# STM32N655 register map
File version: 1.0
CPU: CM55 r0p1, little endian, no MPU, FPU, vendor SysTick, 8 interrupt priority bits
Registers are 32-bit, read-write, reset 0x0 unless marked. A register's access mark holds for its fields unless they carry their own. Offsets are from the block's base; [hi:lo] are bit positions; {n}, {i} and the like mark numbered series; 'fields as' and 'values as' point back to an identical list.

## RCC (part 1 of 4) — Reset and clock control
Base 0x46028000
Same registers: RCC_S 0x56028000
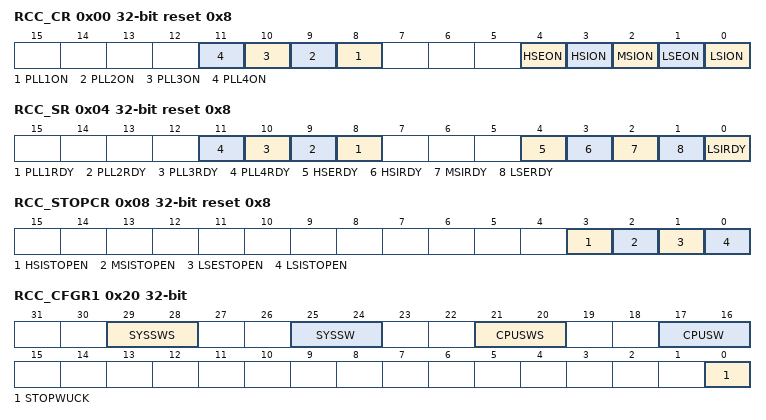
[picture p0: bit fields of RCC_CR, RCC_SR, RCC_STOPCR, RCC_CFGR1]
0x00 RCC_CR reset 0x8 — RCC control register
  [n+7] PLL{n}ON (n=1..4) — PLL{n} enable in Run/Sleep mode.
    0=PLL{n} is OFF (default after reset); 1=PLL{n} is ON
  [4] HSEON — HSE oscillator enable in Run/Sleep mode.
    0=HSE is OFF (default after reset); 1=HSE is ON
  [3] HSION — HSI oscillator enable in Run/Sleep mode.
    0=HSI is OFF; 1=HSI is ON (default after reset)
  [2] MSION — MSI oscillator enable in Run/Sleep mode.
    0=MSI is OFF (default after reset); 1=MSI is ON
  [1] LSEON — LSE oscillator enable in Run/Sleep mode.
    0=LSE is OFF (default after reset); 1=LSE is ON
  [0] LSION — LSI oscillator enable in Run/Sleep mode.
    0=LSI is OFF (default after reset); 1=LSI is ON
0x04 RCC_SR ro reset 0x8 — RCC status register
  [n+7] PLL{n}RDY (n=1..4) — PLL{n} clock ready flag
    0=PLL{n} unlocked (default after reset); 1=PLL{n} locked
  [4] HSERDY — HSE clock ready flag
    0=HSE is not ready (default after reset); 1=HSE is ready
  [3] HSIRDY — HSI clock ready flag
    0=HSI is not ready; 1=HSI is ready (default after reset)
  [2] MSIRDY — MSI clock ready flag
    0=MSI is not ready (default after reset); 1=MSI is ready
  [1] LSERDY — LSE clock ready flag
    0=LSE is not ready (default after reset); 1=LSE is ready
  [0] LSIRDY — LSI clock ready flag
    0=LSI is not ready (default after reset); 1=LSI is ready
0x08 RCC_STOPCR reset 0x8 — RCC Stop mode control register
  [3] HSISTOPEN — HSI oscillator enable in Stop mode.
    0=HSI is OFF; 1=HSI is ON (default after reset)
  [2] MSISTOPEN — MSI oscillator enable in Stop mode.
    0=MSI is OFF (default after reset); 1=MSI is ON
  [1] LSESTOPEN — LSE oscillator enable in Stop mode.
    0=LSE is OFF (default after reset); 1=LSE is ON
  [0] LSISTOPEN — LSI oscillator enable in Stop mode.
    0=LSI is OFF (default after reset); 1=LSI is ON
0x20 RCC_CFGR1 access per field — RCC configuration register 1
  [29:28] SYSSWS ro — System clock switch status
    0=hsi_ck selected as system clock (default after reset); 1=msi_ck selected as system clock; 2=hse_ck selected as system clock; 3=ic2_ck selected as system clock
  [25:24] SYSSW rw — System clock switch selection
    values as SYSSWS
  [21:20] CPUSWS ro — CPU clock switch status
    0=hsi_ck selected as system clock (default after reset); 1=msi_ck selected as system clock; 2=hse_ck selected as system clock; 3=ic1_ck selected as system clock
  [17:16] CPUSW rw — CPU clock switch selection
    values as CPUSWS
  [0] STOPWUCK rw — System clock selection after a wake up from system Stop.
    0=HSI selected as wake up clock from system Stop (default after reset); 1=CSI selected as wake up clock from system Stop
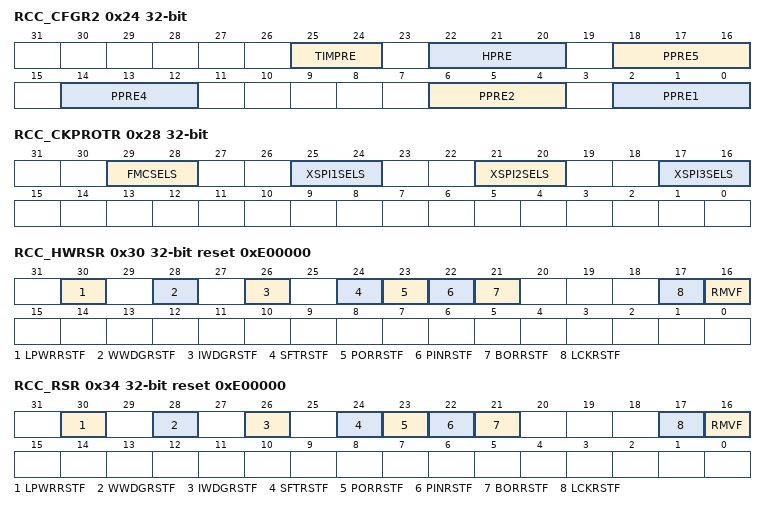
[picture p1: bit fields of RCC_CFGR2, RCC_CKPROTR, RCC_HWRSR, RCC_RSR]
0x24 RCC_CFGR2 — RCC configuration register 2
  [25:24] TIMPRE — Timers clocks prescaler selection
    0=timg_ck = sys_bus_ck (default after reset); 1=timg_ck = sys_bus_ck / 2; 2=timg_ck = sys_bus_ck / 4
  [22:20] HPRE — AHB clock prescaler
    0=sys_bus2_ck= sys_bus_ck; 1=sys_bus2_ck = sys_bus_ck / 2 (default after reset); 2=sys_bus2_ck= sys_bus_ck / 4; 3=sys_bus2_ck = sys_bus_ck / 8; 4=sys_bus2_ck = sys_bus_ck / 16; 5=sys_bus2_ck = sys_bus_ck / 32; 6=sys_bus2_ck = sys_bus_ck / 64; 7=sys_bus2_ck = sys_bus_ck / 128
  [18:16] PPRE5 — CPU domain APB5 prescaler
    0=rcc_pclk5 = sys_bus2_ck (default after reset); 1=rcc_pclk5 = sys_bus2_ck / 2; 2=rcc_pclk1 = sys_bus2_ck / 4; 3=rcc_pclk1 = sys_bus2_ck / 8; 4=rcc_pclk1 = sys_bus2_ck / 16; 5=rcc_pclk1 = sys_bus2_ck / 32; 6=rcc_pclk1 = sys_bus2_ck / 64; 7=rcc_pclk1 = sys_bus2_ck / 128
  [14:12] PPRE4 — CPU domain APB4 prescaler
    0=rcc_pclk4 = sys_bus2_ck (default after reset); 1=rcc_pclk4 = sys_bus2_ck / 2; 2=rcc_pclk1 = sys_bus2_ck / 4; 3=rcc_pclk1 = sys_bus2_ck / 8; 4=rcc_pclk1 = sys_bus2_ck / 16; 5=rcc_pclk1 = sys_bus2_ck / 32; 6=rcc_pclk1 = sys_bus2_ck / 64; 7=rcc_pclk1 = sys_bus2_ck / 128
  [6:4] PPRE2 — CPU domain APB2 prescaler
    0=rcc_pclk2 = sys_bus2_ck (default after reset); 1=rcc_pclk2 = sys_bus2_ck / 2; 2=rcc_pclk1 = sys_bus2_ck / 4; 3=rcc_pclk1 = sys_bus2_ck / 8; 4=rcc_pclk1 = sys_bus2_ck / 16; 5=rcc_pclk1 = sys_bus2_ck / 32; 6=rcc_pclk1 = sys_bus2_ck / 64; 7=rcc_pclk1 = sys_bus2_ck / 128
  [2:0] PPRE1 — CPU domain APB1 prescaler
    0=rcc_pclk1 = sys_bus2_ck (default after reset); 1=rcc_pclk1 = sys_bus2_ck / 2; 2=rcc_pclk1 = sys_bus2_ck / 4; 3=rcc_pclk1 = sys_bus2_ck / 8; 4=rcc_pclk1 = sys_bus2_ck / 16; 5=rcc_pclk1 = sys_bus2_ck / 32; 6=rcc_pclk1 = sys_bus2_ck / 64; 7=rcc_pclk1 = sys_bus2_ck / 128
0x28 RCC_CKPROTR ro — RCC clock protection register
  [29:28] FMCSELS — FMC clock selection current status
    0=hclk5 selected as FMC clock (default after reset); 1=per_ck selected as FMC clock; 2=ic3_ck selected as FMC clock; 3=ic4_ck selected as FMC clock
  [25:24] XSPI1SELS — XSPI1 clock selection current status
    0=hclk5 selected as XSPI1 clock (default after reset); 1=per_ck selected as XSPI1 clock; 2=ic3_ck selected as XSPI1 clock; 3=ic4_ck selected as XSPI1 clock
  [21:20] XSPI2SELS — XSPI2 clock selection current status
    0=hclk5 selected as XSPI2 clock (default after reset); 1=per_ck selected as XSPI2 clock; 2=ic3_ck selected as XSPI2 clock; 3=ic4_ck selected as XSPI2 clock
  [17:16] XSPI3SELS — XSPI3 clock selection current status
    0=hclk5 selected as XSPI3 clock (default after reset); 1=per_ck selected as XSPI3 clock; 2=ic3_ck selected as XSPI3 clock; 3=ic4_ck selected as XSPI3 clock
0x2C RCC_BDCR — RCC backup domain protection register
  [31] VSWRST — VSW domain software reset.
    0=VSW domain is not reset (default after reset); 1=VSW domain is reset
0x30 RCC_HWRSR access per field reset 0xE00000 — RCC reset status register for hardware
  [30] LPWRRSTF ro — Illegal Stop or Standby flag.
    0=no illegal reset occurred (default after power-on reset); 1=illegal Stop or Standby reset occurred
  [28] WWDGRSTF ro — Window watchdog reset flag
    0=no Window Watchdog Reset occurred from WWDG (default after power-on reset); 1=Window Watchdog Reset occurred from WWDG
  [26] IWDGRSTF ro — Independent Watchdog reset flag.
    0=no Independent Watchdog Reset occurred (default after power-on reset); 1=Independent Watchdog Reset occurred
  [24] SFTRSTF ro — Software system reset flag (1)
    0=no Software System reset occurred (default after power-on reset); 1=a Software System reset has been generated by the CPU
  [23] PORRSTF ro — POR/PDR flag.
    0=no POR/PDR reset occurred; 1=POR/PDR reset occurred (default after power-on reset)
  [22] PINRSTF ro — Pin reset flag (NRST)
    0=no reset from pin occurred; 1=Reset from Pin occurred (default after power-on reset)
  [21] BORRSTF ro — BOR flag
    0=no BOR occurred; 1=BOR occurred (default after power-on reset)
  [17] LCKRSTF ro — CPU lockup reset flag.
    0=No reset from CPU lockup occurred; 1=Reset from CPU lockup occurred
  [16] RMVF wo — Remove reset flag
    0=clear of the reset flags not activated (default after power-on reset); 1=clear the value of the reset flags
0x34 RCC_RSR access per field reset 0xE00000 — RCC reset register
  [30] LPWRRSTF ro — Illegal Stop or Standby flag.
    values as RCC_HWRSR.LPWRRSTF
  [28] WWDGRSTF ro — Window Watchdog reset flag
    0=no Window Watchdog reset occurred from WWDG (default after power-on reset); 1=Window Watchdog reset occurred from WWDG
  [26] IWDGRSTF ro — Independent Watchdog reset flag.
    0=no Independent Watchdog reset occurred (default after power-on reset); 1=Independent Watchdog reset occurred
  [24] SFTRSTF ro — Software System reset flag (1)
    values as RCC_HWRSR.SFTRSTF
  [23] PORRSTF ro — POR/PDR flag.
    values as RCC_HWRSR.PORRSTF
  [22] PINRSTF ro — Pin reset flag (NRST)
    0=no reset from Pin occurred; 1=Reset from Pin occurred (default after power-on reset)
  [21] BORRSTF ro — BOR flag
    values as RCC_HWRSR.BORRSTF
  [17] LCKRSTF ro — CPU lockup reset flag.
    values as RCC_HWRSR.LCKRSTF
  [16] RMVF wo — Remove reset flag
    values as RCC_HWRSR.RMVF
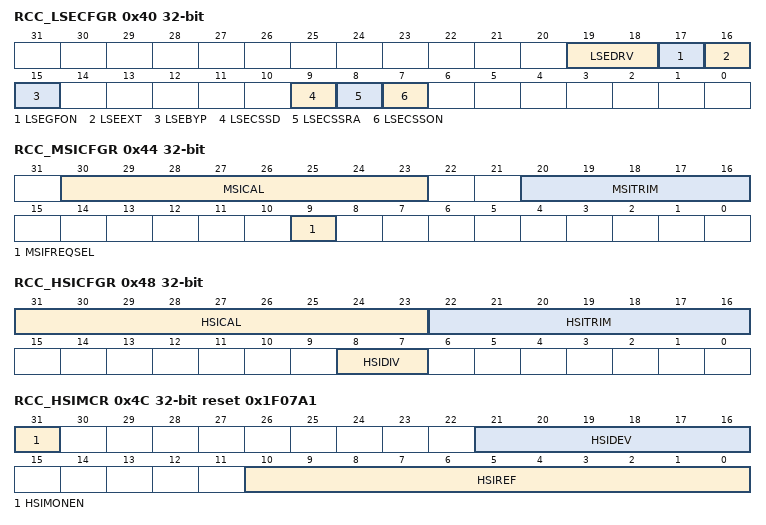
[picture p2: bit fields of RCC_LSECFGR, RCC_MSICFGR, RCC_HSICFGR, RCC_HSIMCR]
0x40 RCC_LSECFGR access per field — RCC LSE configuration register
  [19:18] LSEDRV rw — LSE oscillator driving capability
    0=Lowest drive (default after reset); 1=Medium low drive; 2=Medium high drive; 3=Highest drive
  [17] LSEGFON rw — LSE clock glitch filter enable
    0=LSE clock glitch filter is disabled (default after reset); 1=LSE clock glitch filter is enabled
  [16] LSEEXT rw — LSE clock type in Bypass mode
    0=LSE in analog mode (default after reset); 1=LSE in digital mode
  [15] LSEBYP rw — LSE clock bypass
    0=LSE oscillator not bypassed (default after reset); 1=LSE oscillator bypassed with an external clock
  [9] LSECSSD ro — LSE clock security system (CSS) failure detection
    0=No failure detected on the oscillator (default after reset); 1=Failure detected on the oscillator
  [8] LSECSSRA rw — LSE clock security system (CSS) re-arm function
    0=Writing 0 has no effect (default after reset); 1=Writing 1 generates a re-arm pulse for the LSECSS function
  [7] LSECSSON wo — LSE clock security system (CSS) enable
    0=clock Security System on the LSE oscillator OFF (default after reset); 1=clock Security System on the LSE oscillator ON
0x44 RCC_MSICFGR access per field — RCC MSI configuration register
  [30:23] MSICAL ro — MSI clock calibration
  [20:16] MSITRIM rw — MSI clock trimming
  [9] MSIFREQSEL rw — MSI oscillator frequency select
    0=MSI oscillator frequency is 4 MHz (default after backup domain reset); 1=MSI oscillator frequency is 16 MHz
0x48 RCC_HSICFGR access per field — RCC HSI configuration register
  [31:23] HSICAL ro — HSI clock calibration
  [22:16] HSITRIM rw — HSI clock trimming
    64=bsec_hsi_cal[8:0] - 64; 65=bsec_hsi_cal[8:0] - 63; 0=bsec_hsi_cal[8:0] (default after reset); 62=bsec_hsi_cal[8:0] + 62; 63=bsec_hsi_cal[8:0] + 63
  [8:7] HSIDIV rw — HSI clock divider
    0=hsi_ck = hsi_osc_ck (default after reset); 1=hsi_ck = hsi_osc_ck / 2
0x4C RCC_HSIMCR reset 0x1F07A1 — RCC HSI monitor control register
  [31] HSIMONEN — HSI clock period monitor enable
    0=Writing '0' disables the HSI clock period monitoring, reading '0' means that the HSI clock period monitoring is disabled; 1=Writing '1' enables the HSI clock period monitoring, reading '1' means that the HSI clock period monitoring is enabled
  [21:16] HSIDEV — HSI clock count deviation value
  [10:0] HSIREF — HSI clock cycle counter reference value.
0x50 RCC_HSIMSR ro — RCC HSI monitor status register
  [10:0] HSIVAL — HSI clock cycle counter measured value.
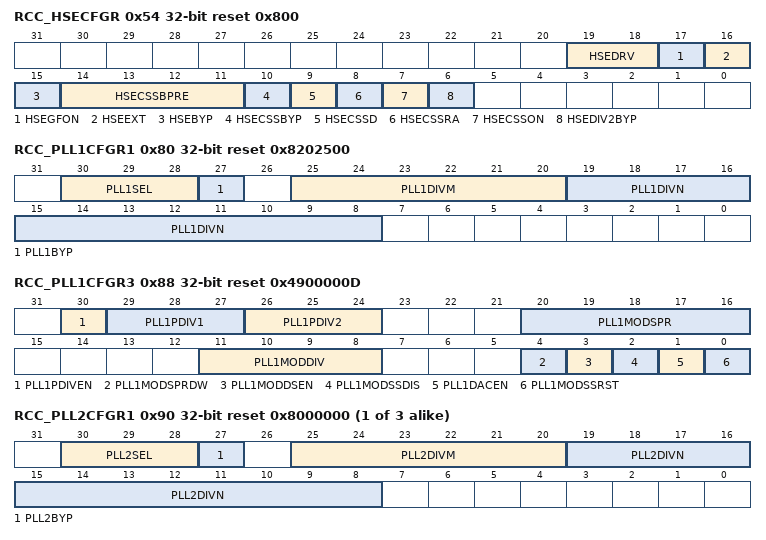
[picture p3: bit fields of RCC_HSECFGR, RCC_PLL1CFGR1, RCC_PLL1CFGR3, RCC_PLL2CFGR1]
0x54 RCC_HSECFGR access per field reset 0x800 — RCC HSE configuration register
  [19:18] HSEDRV rw — HSE oscillator driving capability
    values as RCC_LSECFGR.LSEDRV
  [17] HSEGFON rw — HSE clock glitch filter enable
    values as RCC_LSECFGR.LSEGFON
  [16] HSEEXT rw — HSE clock type in Bypass mode
    0=HSE in analog mode (default after reset); 1=HSE in digital mode
  [15] HSEBYP rw — HSE clock bypass
    0=HSE oscillator not bypassed (default after reset); 1=HSE oscillator bypassed with an external clock
  [14:11] HSECSSBPRE rw — HSE clock security system (CSS) bypass divider
    0=HSI clock is divided by 1; 1=HSI clock is divided by 2 (default after reset); 2=HSI clock is divided by 3; 3=HSI clock is divided by 4; 15=HSI clock is divided by 15
  [10] HSECSSBYP rw — HSE clock security system (CSS) bypass enable
    0=clock Security System Bypass of the HSE oscillator is OFF (default after reset); 1=clock Security System Bypass on the HSE oscillator is ON
  [9] HSECSSD ro — HSE clock security system (CSS) failure detection
    values as RCC_LSECFGR.LSECSSD
  [8] HSECSSRA rw — HSE clock security system (CSS) re-arm function
    0=Writing 0 has no effect (default after reset); 1=Writing 1 generates a re-arm pulse for the HSECSS function
  [7] HSECSSON rw — HSE clock security system (CSS) enable
    0=clock Security System on the HSE oscillator OFF (default after reset); 1=clock Security System on the HSE oscillator ON
  [6] HSEDIV2BYP rw — HSE div2 oscillator clock in Bypass mode
    0=HSE: hse_div2_osc_ck = hse_osc_ck/2 (default after reset); 1=HSE: hse_div2_osc_ck = hse_osc_ck
0x80 RCC_PLL1CFGR1 reset 0x8202500 — RCC PLL1 configuration register 1
  [30:28] PLL1SEL — PLL1 source selection of the reference clock
    0=hsi_ck selected as reference clock; 1=msi_ck selected as reference clock; 2=hse_ck selected as reference clock; 3=I2S_CKIN selected as reference clock
  [27] PLL1BYP — PLL1 bypass
    0=PLL output is driven by the VCO, via the optional POSTDIV division; 1=PLL output is bypassed and driven by the PLL reference clock (default after reset)
  [25:20] PLL1DIVM — PLL1 reference input clock divide frequency ratio
    0=Not applicable when PLL is enabled; 1=reference clock is divided by 1 (min value); 2=reference clock is divided by 2; 63=reference clock is divided by 63
  [19:8] PLL1DIVN — PLL1 Integer part for the VCO multiplication factor
0x84 RCC_PLL1CFGR2 reset 0x800000 — RCC PLL1 configuration register 2
  [23:0] PLL1DIVNFRAC — PLL1 Fractional part of the VCO multiplication factor
0x88 RCC_PLL1CFGR3 reset 0x4900000D — RCC PLL1 configuration register 3
  [30] PLL1PDIVEN — PLL1 post divider POSTDIV1, POSTDIV2, and PLL clock output enable
    0=POSTDIV1 and POSTDIV2 are powered down; 1=POSTDIV1 and POSTDIV2 dividers are active (default after reset)
  [29:27] PLL1PDIV1 — PLL1 VCO frequency divider level 1
    0=Not applicable; 1=VCO output is divided by 1 (minimum value) (default after reset); 7=VCO output is divided by 7
  [26:24] PLL1PDIV2 — PLL1 VCO frequency divider level 2
    values as PLL1PDIV1
  [20:16] PLL1MODSPR — PLL1 Modulation Spread depth adjustment
  [11:8] PLL1MODDIV — PLL1 Modulation Division frequency adjustment
  [4] PLL1MODSPRDW — PLL1 Modulation Spread-Spectrum Down
    0=Center-spread modulation selected (default after reset); 1=Down-spread modulation selected
  [3] PLL1MODDSEN — PLL1 Modulation Spread-Spectrum (and Fractional Divide) enable
    0=Modulation Spread-Spectrum and Fractional Divide are not active; 1=Modulation Spread-Spectrum and Fractional Divide are active (default after reset)
  [2] PLL1MODSSDIS — PLL1 Modulation Spread-Spectrum Disable
    0=Modulation Spread-Spectrum is active (and Fractional Divide inactive); 1=Fractional Divide is active (and the Modulation Spread-Spectrum inactive) (default after reset)
  [1] PLL1DACEN — PLL1 noise canceling DAC enable in fractional mode.
    0=DAC is not active (default after reset); 1=DAC is active
  [0] PLL1MODSSRST — PLL1 Modulation Spread Spectrum reset
    0=The PLL1 modulation Spread Spectrum reset module is released; 1=The PLL1 modulation Spread Spectrum reset module is asserted (default after reset)
{0x70+0x10*i} RCC_PLL{i}CFGR1 reset 0x8000000 (i=2..4) — RCC PLL{i} configuration register 1
  [30:28] PLL{i}SEL — PLL{i} source selection of the reference clock
    values as RCC_PLL1CFGR1.PLL1SEL
  [27] PLL{i}BYP — PLL{i} bypass
    values as RCC_PLL1CFGR1.PLL1BYP
  [25:20] PLL{i}DIVM — PLL{i} reference input clock divide frequency ratio
    values as RCC_PLL1CFGR1.PLL1DIVM
  [19:8] PLL{i}DIVN — PLL{i} Integer part for the VCO multiplication factor
{0x74+0x10*i} RCC_PLL{i}CFGR2 (i=2..4) — RCC PLL{i} configuration register 2
  [23:0] PLL{i}DIVNFRAC — PLL{i} Fractional part of the VCO multiplication factor
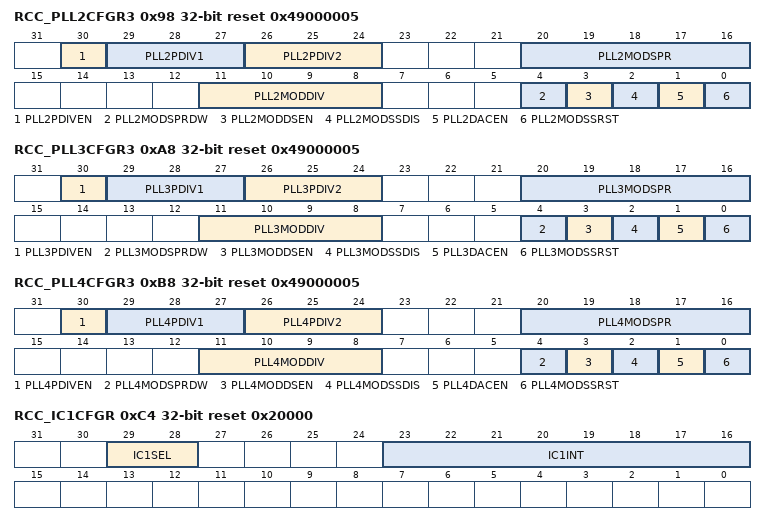
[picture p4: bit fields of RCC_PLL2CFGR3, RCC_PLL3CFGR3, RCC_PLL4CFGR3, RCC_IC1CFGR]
0x98 RCC_PLL2CFGR3 reset 0x49000005 — RCC PLL2 configuration register 3
  [30] PLL2PDIVEN — PLL2 post divider POSTDIV1, POSTDIV2, and PLL clock output enable
    values as RCC_PLL1CFGR3.PLL1PDIVEN
  [29:27] PLL2PDIV1 — PLL2 VCO frequency divider level 1
    values as RCC_PLL1CFGR3.PLL1PDIV1
  [26:24] PLL2PDIV2 — PLL2 VCO frequency divider level 2
    values as RCC_PLL1CFGR3.PLL1PDIV1
  [20:16] PLL2MODSPR — PLL2 Modulation Spread depth adjustment
  [11:8] PLL2MODDIV — PLL2 Modulation Division frequency adjustment
  [4] PLL2MODSPRDW — PLL2 Modulation Down Spread
    values as RCC_PLL1CFGR3.PLL1MODSPRDW
  [3] PLL2MODDSEN — PLL2 Modulation Spread-Spectrum (and Fractional Divide) enable
    0=Modulation Spread-Spectrum and Fractional Divide are not active (default after reset); 1=Modulation Spread-Spectrum and Fractional Divide are active
  [2] PLL2MODSSDIS — PLL2 Modulation Spread-Spectrum Disable
    values as RCC_PLL1CFGR3.PLL1MODSSDIS
  [1] PLL2DACEN — PLL2 noise canceling DAC enable in fractional mode.
    0=DAC is not active (default after reset); 1=DAC is active
  [0] PLL2MODSSRST — PLL2 Modulation Spread Spectrum reset
    0=The PLL2 Modulation Spread Spectrum reset module is released; 1=The PLL2 Modulation Spread Spectrum reset module is asserted (default after reset)
0xA8 RCC_PLL3CFGR3 reset 0x49000005 — RCC PLL3 configuration register 3
  [30] PLL3PDIVEN — PLL3 post divider POSTDIV1, POSTDIV2, and PLL clock output enable
    values as RCC_PLL1CFGR3.PLL1PDIVEN
  [29:27] PLL3PDIV1 — PLL3 VCO frequency divider level 1
    values as RCC_PLL1CFGR3.PLL1PDIV1
  [26:24] PLL3PDIV2 — PLL3 VCO frequency divider level 2
    values as RCC_PLL1CFGR3.PLL1PDIV1
  [20:16] PLL3MODSPR — PLL3 Modulation Spread depth adjustment
  [11:8] PLL3MODDIV — PLL3 Modulation Division frequency adjustment
  [4] PLL3MODSPRDW — PLL3 Modulation Down Spread
    values as RCC_PLL1CFGR3.PLL1MODSPRDW
  [3] PLL3MODDSEN — PLL3 Modulation Spread-Spectrum (and Fractional Divide) enable
    values as RCC_PLL2CFGR3.PLL2MODDSEN
  [2] PLL3MODSSDIS — PLL3 Modulation Spread-Spectrum Disable
    values as RCC_PLL1CFGR3.PLL1MODSSDIS
  [1] PLL3DACEN — PLL3 noise canceling DAC enable in fractional mode.
    0=DAC is not active (default after reset); 1=DAC is active
  [0] PLL3MODSSRST — PLL3 Modulation Spread Spectrum reset
    0=The PLL3 modulation Spread Spectrum reset module is released; 1=The PLL3 modulation Spread Spectrum reset module is asserted (default after reset)
0xB8 RCC_PLL4CFGR3 reset 0x49000005 — RCC PLL4 configuration register 3
  [30] PLL4PDIVEN — PLL4 post divider POSTDIV1, POSTDIV2, and PLL clock output enable
    values as RCC_PLL1CFGR3.PLL1PDIVEN
  [29:27] PLL4PDIV1 — PLL4 VCO frequency divider level 1
    values as RCC_PLL1CFGR3.PLL1PDIV1
  [26:24] PLL4PDIV2 — PLL4 VCO frequency divider level 2
    values as RCC_PLL1CFGR3.PLL1PDIV1
  [20:16] PLL4MODSPR — PLL4 Modulation Spread depth adjustment
  [11:8] PLL4MODDIV — PLL4 Modulation Division frequency adjustment
  [4] PLL4MODSPRDW — PLL4 Modulation Down Spread
    values as RCC_PLL1CFGR3.PLL1MODSPRDW
  [3] PLL4MODDSEN — PLL4 Modulation Spread-Spectrum (and Fractional Divide) enable
    values as RCC_PLL2CFGR3.PLL2MODDSEN
  [2] PLL4MODSSDIS — PLL4 Modulation Spread-Spectrum Disable
    values as RCC_PLL1CFGR3.PLL1MODSSDIS
  [1] PLL4DACEN — PLL4 noise canceling DAC enable in fractional mode.
    0=DAC is not active (default after reset); 1=DAC is active
  [0] PLL4MODSSRST — PLL4 Modulation Spread Spectrum reset
    0=The PLL4 modulation Spread Spectrum reset module is released; 1=The PLL4 modulation Spread Spectrum reset module is asserted (default after reset)
0xC4 RCC_IC1CFGR reset 0x20000 — RCC IC1 configuration register
  [29:28] IC1SEL — Divider IC1 Source Selection
    0=pll1_ck is selected (default after reset); 1=pll2_ck is selected; 2=hsi_ck = hsi_osc_ck / 4; 3=hsi_ck = hsi_osc_ck / 8
  [23:16] IC1INT — Divider IC1 integer division factor
    0=IC1 = pllx_ck; 1=IC1 = pllx_ck / 2; 2=IC1 = pllx_ck / 3 (default after reset); 3=IC1 = pllx_ck / 4; 255=IC1 = pllx_ck / 256
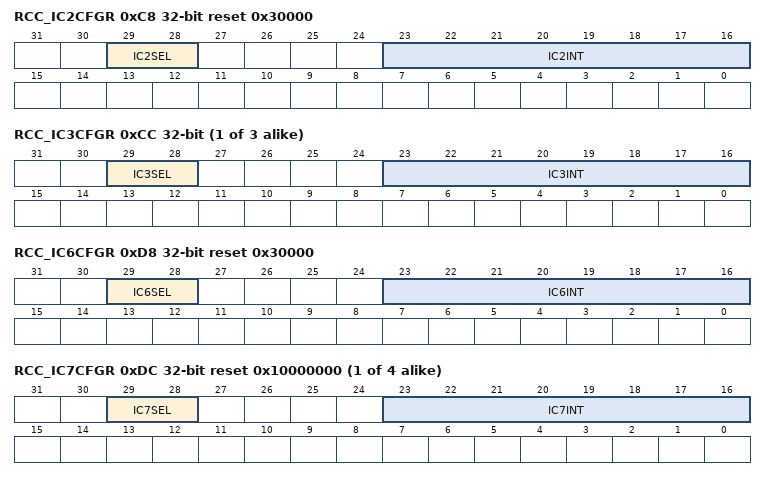
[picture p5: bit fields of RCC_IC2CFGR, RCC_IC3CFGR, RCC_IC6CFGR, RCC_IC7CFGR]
0xC8 RCC_IC2CFGR reset 0x30000 — RCC IC2 configuration register
  [29:28] IC2SEL — Divider IC2 Source Selection
    values as RCC_IC1CFGR.IC1SEL
  [23:16] IC2INT — Divider IC2 integer division factor
    0=IC2 = pllx_ck; 1=IC2 = pllx_ck / 2; 2=IC2 = pllx_ck / 3; 3=IC2 = pllx_ck / 4 (default after reset); 255=IC2 = pllx_ck / 256
{0xC0+4i} RCC_IC{i}CFGR (i=3..5) — RCC IC{i} configuration register
  [29:28] IC{i}SEL — Divider IC{i} Source Selection
    values as RCC_IC1CFGR.IC1SEL
  [23:16] IC{i}INT — Divider IC{i} integer division factor
    0=IC{i} = pllx_ck (default after reset); 1=IC{i} = pllx_ck / 2; 2=IC{i} = pllx_ck / 3; 3=IC{i} = pllx_ck / 4; 255=IC{i} = pllx_ck / 256
0xD8 RCC_IC6CFGR reset 0x30000 — RCC IC6 configuration register
  [29:28] IC6SEL — Divider IC6 Source Selection
    values as RCC_IC1CFGR.IC1SEL
  [23:16] IC6INT — Divider IC6 integer division factor
    0=IC6 = pllx_ck; 1=IC6 = pllx_ck / 2; 2=IC6 = pllx_ck / 3; 3=IC6 = pllx_ck / 4 (default after reset); 255=IC6 = pllx_ck / 256
{0xC0+4i} RCC_IC{i}CFGR reset 0x10000000 (i=7..10) — RCC IC{i} configuration register
  [29:28] IC{i}SEL — Divider IC{i} Source Selection
    0=pll1_ck is selected; 1=pll2_ck is selected (default after reset); 2=hsi_ck = hsi_osc_ck / 4; 3=hsi_ck = hsi_osc_ck / 8
  [23:16] IC{i}INT — Divider IC{i} integer division factor
    values as RCC_IC3CFGR.IC{i}INT
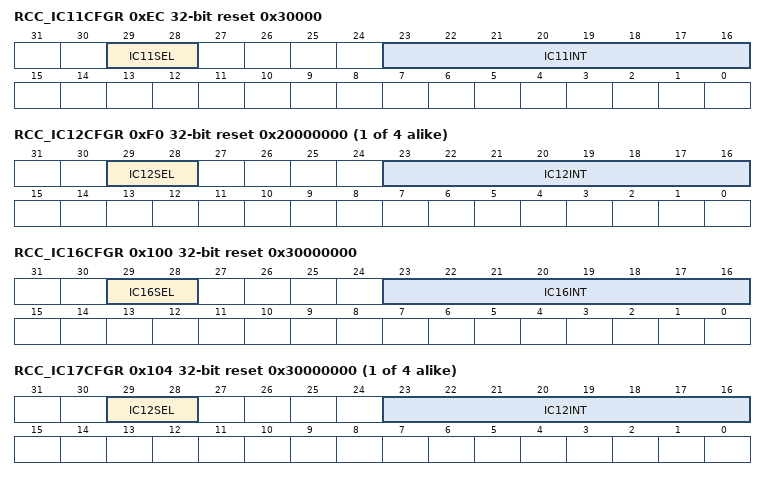
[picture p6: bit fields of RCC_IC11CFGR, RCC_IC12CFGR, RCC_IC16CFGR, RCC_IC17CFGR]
0xEC RCC_IC11CFGR reset 0x30000 — RCC IC11 configuration register
  [29:28] IC11SEL — Divider IC11 Source Selection
    values as RCC_IC1CFGR.IC1SEL
  [23:16] IC11INT — Divider IC11 integer division factor
    0=IC11 = pllx_ck; 1=IC11 = pllx_ck / 2; 2=IC11 = pllx_ck / 3; 3=IC11 = pllx_ck / 4 (default after reset); 255=IC11 = pllx_ck / 256
{0xC0+4i} RCC_IC{i}CFGR reset 0x20000000 (i=12..15) — RCC IC{i} configuration register
  [29:28] IC{i}SEL — Divider IC{i} Source Selection
    0=pll1_ck is selected; 1=pll2_ck is selected; 2=hsi_ck = hsi_osc_ck / 4; 3=hsi_ck = hsi_osc_ck / 8
  [23:16] IC{i}INT — Divider IC{i} integer division factor
    values as RCC_IC3CFGR.IC{i}INT
0x100 RCC_IC16CFGR reset 0x30000000 — RCC IC16 configuration register
  [29:28] IC16SEL — Divider IC16 Source Selection
    values as RCC_IC12CFGR.IC{i}SEL
  [23:16] IC16INT — Divider IC16 integer division factor
    1=IC16 = pllx_ck / 2; 2=IC16 = pllx_ck / 3; 3=IC16 = pllx_ck / 4; 255=IC16 = pllx_ck / 256
{0xC0+4i} RCC_IC{i}CFGR reset 0x30000000 (i=17..20) — RCC IC{i} configuration register
  fields as RCC_IC12CFGR
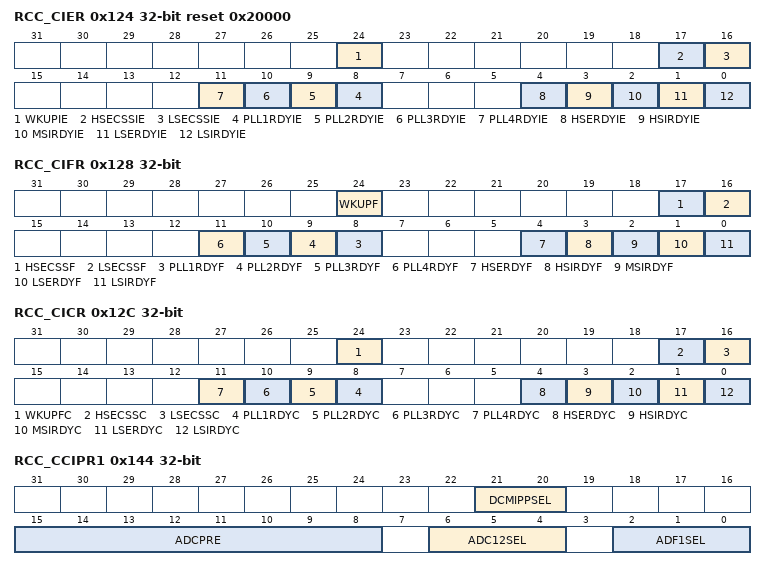
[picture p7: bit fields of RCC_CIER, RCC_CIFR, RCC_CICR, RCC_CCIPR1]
0x124 RCC_CIER reset 0x20000 — RCC clock-source interrupt enable register
  [24] WKUPIE — CPU wakeup from Stop interrupt enable
    0=Wakeup interrupt disabled (default after reset); 1=Wakeup interrupt enabled
  [17] HSECSSIE — HSE clock security system (CSS) interrupt enable
    0=HSE CSS interrupt disabled; 1=HSE CSS interrupt enabled (default after reset)
  [16] LSECSSIE — LSE clock security system (CSS) interrupt enable
    0=LSE CSS interrupt disabled (default after reset); 1=LSE CSS interrupt enabled
  [n+7] PLL{n}RDYIE (n=1..4) — PLL{n} ready interrupt enable
    0=PLL{n} lock interrupt disabled (default after reset); 1=PLL{n} lock interrupt enabled
  [4] HSERDYIE — HSE ready interrupt enable
    0=HSE ready interrupt disabled (default after reset); 1=HSE ready interrupt enabled
  [3] HSIRDYIE — HSI ready interrupt enable
    0=HSI ready interrupt disabled (default after reset); 1=HSI ready interrupt enabled
  [2] MSIRDYIE — MSI ready interrupt enable
    0=MSI ready interrupt disabled (default after reset); 1=MSI ready interrupt enabled
  [1] LSERDYIE — LSE ready interrupt enable
    0=LSE ready interrupt disabled (default after reset); 1=LSE ready interrupt enabled
  [0] LSIRDYIE — LSI ready interrupt enable
    0=LSI ready interrupt disabled (default after reset); 1=LSI ready interrupt enabled
0x128 RCC_CIFR ro — RCC clock-source interrupt flag register
  [24] WKUPF — CPU wakeup from Stop interrupt flag
    0=no wakeup interrupt caused by the PWR (default after reset); 1=wakeup interrupt caused by the PWR
  [17] HSECSSF — HSE ready interrupt flag
    0=no clock ready interrupt caused by the HSE (default after reset); 1=clock ready interrupt caused by the HSE
  [16] LSECSSF — LSE ready interrupt flag
    0=no clock ready interrupt caused by the LSE (default after reset); 1=clock ready interrupt caused by the LSE
  [n+7] PLL{n}RDYF (n=1..4) — PLL{n} ready interrupt flag
    0=no clock ready interrupt caused by the PLL{n} (default after reset); 1=clock ready interrupt caused by the PLL{n}
  [4] HSERDYF — HSE ready interrupt flag
    values as HSECSSF
  [3] HSIRDYF — HSI ready interrupt flag
    0=no clock ready interrupt caused by the HSI (default after reset); 1=clock ready interrupt caused by the HSI
  [2] MSIRDYF — MSI ready interrupt flag
    0=no clock ready interrupt caused by the MSI (default after reset); 1=clock ready interrupt caused by the MSI
  [1] LSERDYF — LSE ready interrupt flag
    values as LSECSSF
  [0] LSIRDYF — LSI ready interrupt flag
    0=no clock ready interrupt caused by the LSI (default after reset); 1=clock ready interrupt caused by the LSI
0x12C RCC_CICR wo — RCC clock-source interrupt Clear register
  [24] WKUPFC — CPU Wakeup ready interrupt clear
    0=WKUPF not modified (default after reset); 1=WKUPF cleared
  [17] HSECSSC — HSE ready interrupt clear
    0=HSECSSF not modified (default after reset); 1=HSECSSF cleared
  [16] LSECSSC — LSE ready interrupt clear
    0=LSECSSF not modified (default after reset); 1=LSECSSF cleared
  [n+7] PLL{n}RDYC (n=1..4) — PLL{n} ready interrupt clear
    0=PLL{n}RDYF not modified (default after reset); 1=PLL{n}RDYF cleared
  [4] HSERDYC — HSE ready interrupt clear
    0=HSERDYF not modified (default after reset); 1=HSERDYF cleared
  [3] HSIRDYC — HSI ready interrupt clear
    0=HSIRDYF not modified (default after reset); 1=HSIRDYF cleared
  [2] MSIRDYC — MSI ready interrupt clear
    0=MSIRDYF not modified (default after reset); 1=MSIRDYF cleared
  [1] LSERDYC — LSE ready interrupt clear
    0=LSERDYF not modified (default after reset); 1=LSERDYF cleared
  [0] LSIRDYC — LSI ready interrupt clear
    0=LSIRDYF not modified (default after reset); 1=LSIRDYF cleared
0x144 RCC_CCIPR1 — RCC clock configuration for independent peripheral register1
  [21:20] DCMIPPSEL — Source selection for the DCMIPP kernel clock
    0=pclk5 selected as reference clock; 1=per_ck selected as reference clock; 2=ic17_ck selected as reference clock; 3=hsi_div_ck selected as reference clock
  [15:8] ADCPRE — ADC12 Prog clock divider selection (for clock ck_icn_p_adf1)
    {v}=ck_icn_p_adf1 is divided by {v+1} (v=0..3)
  [6:4] ADC12SEL — Source selection for the ADC12 kernel clock
    0=hclk1 selected as reference clock; 1=per_ck selected as reference clock; 2=ic7_ck selected as reference clock; 3=ic8_ck selected as reference clock; 4=msi_ck selected as reference clock; 5=hsi_div_ck selected as reference clock; 6=I2S_CKIN selected as reference clock; 7=timg_ck selected as reference clock
  [2:0] ADF1SEL — Source selection for the ADF1 kernel clock
    0=hclk2 selected as reference clock; 1=per_ck selected as reference clock; 2=ic7_ck selected as reference clock; 3=ic8_ck selected as reference clock; 4=msi_ck selected as reference clock; 5=hsi_div_ck selected as reference clock; 6=I2S_CKIN selected as reference clock; 7=timg_ck selected as reference clock
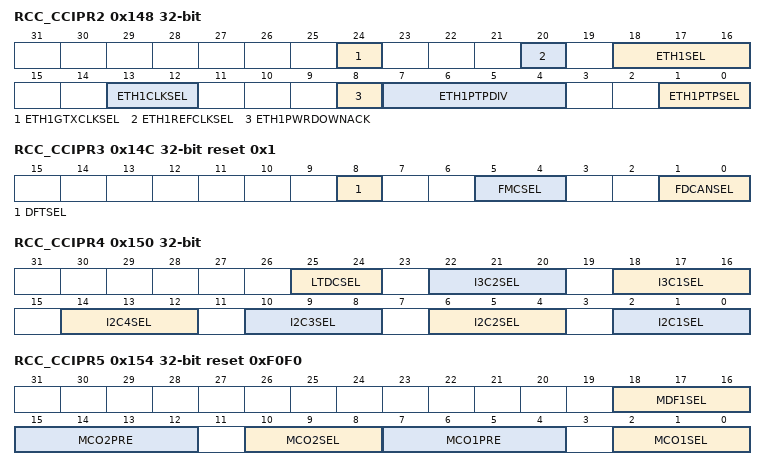
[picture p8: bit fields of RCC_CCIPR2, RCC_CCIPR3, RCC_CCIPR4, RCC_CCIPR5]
0x148 RCC_CCIPR2 access per field — RCC clock configuration for independent peripheral register 2
  [24] ETH1GTXCLKSEL rw — Set and reset by software.
    0=MII; 1=RGMII
  [20] ETH1REFCLKSEL rw — Set and reset by software
  [18:16] ETH1SEL rw — Set and reset by software
  [13:12] ETH1CLKSEL rw — Source selection for the ETH1 kernel clock
    0=hclke selected as reference clock; 1=per_ck selected as reference clock; 2=ic12_ck selected as reference clock; 3=hse_ck selected as reference clock
  [8] ETH1PWRDOWNACK ro — Set and reset by software.
    0=Power-down sequence start not yet acknowledged; 1=Power-down sequence start acknowledged
  [7:4] ETH1PTPDIV rw — ETH1 Kernel clock divider selection (for clock ck_ker_eth1ptp)
    {v}=ck_ker_eth1ptp is divided by {v+1} (v=0..3); 15=ck_ker_eth1ptp is divided by 16
  [1:0] ETH1PTPSEL rw — Source selection for the ETH1 kernel clock
    0=hclke selected as reference clock; 1=per_ck selected as reference clock; 2=ic13_ck selected as reference clock; 3=hse_ck selected as reference clock
0x14C RCC_CCIPR3 reset 0x1 — RCC clock configuration for independent peripheral register3
  [8] DFTSEL — Source selection for the DFT kernel clock
    0=jtag_tck selected as reference clock (default after reset); 1=pclk3 selected as reference clock
  [5:4] FMCSEL — Source selection for the FMC kernel clock
    0=hclk5 selected as reference clock; 1=per_ck selected as reference clock; 2=ic3_ck selected as reference clock; 3=ic4_ck selected as reference clock
  [1:0] FDCANSEL — Source selection for the FDCAN kernel clock
    0=pclk1 selected as reference clock; 1=per_ck selected as reference clock; 2=ic19_ck selected as reference clock; 3=hse_ck selected as reference clock
0x150 RCC_CCIPR4 — RCC clock configuration for independent peripheral register4
  [25:24] LTDCSEL — Source selection for the LTDC kernel clock
    0=pclk5 selected as reference clock; 1=per_ck selected as reference clock; 2=ic16_ck selected as reference clock; 3=hsi_div_ck selected as reference clock
  [22:20] I3C2SEL — Source selection for the I3C2 kernel clock
    0=pclk1 selected as reference clock; 1=per_ck selected as reference clock; 2=ic10_ck selected as reference clock; 3=ic15_ck selected as reference clock; 4=msi_ck selected as reference clock; 5=hsi_div_ck selected as reference clock
  [18:16] I3C1SEL — Source selection for the I3C1 kernel clock
    values as I3C2SEL
  [4n-2:4n-4] I2C{n}SEL (n=1..4) — Source selection for the I2C{n} kernel clock
    values as I3C2SEL
0x154 RCC_CCIPR5 reset 0xF0F0 — RCC lock configuration for independent peripheral register5
  [18:16] MDF1SEL — Source selection for the MDF1 kernel clock
    values as RCC_CCIPR1.ADF1SEL
  [15:12] MCO2PRE — MCO2 Prog clock divider selection (for clock ck_icn_p_mce4)
    {v}=ck_icn_p_mce4 is divided by {v+1} (v=0..3); 15=ck_icn_p_mce4 is divided by 16
  [10:8] MCO2SEL — Source selection for the MCO2 kernel clock
    0=hsi_div_ck selected as reference clock (default after reset); 1=lse_ck selected as reference clock; 2=msi_ck selected as reference clock; 3=lsi_ck selected as reference clock; 4=hse_ck selected as reference clock; 5=ic15_ck selected as reference clock; 6=ic20_ck selected as reference clock; 7=sysb_ck selected as reference clock
  [7:4] MCO1PRE — MCO1 Prog clock divider selection (for clock ck_icn_p_mce3)
    {v}=ck_icn_p_mce3 is divided by {v+1} (v=0..3); 15=ck_icn_p_mce3 is divided by 16
  [2:0] MCO1SEL — Source selection for the MCO1 kernel clock
    0=hsi_div_ck selected as reference clock (default after reset); 1=lse_ck selected as reference clock; 2=msi_ck selected as reference clock; 3=lsi_ck selected as reference clock; 4=hse_ck selected as reference clock; 5=ic5_ck selected as reference clock; 6=ic10_ck selected as reference clock; 7=sysa_ck selected as reference clock
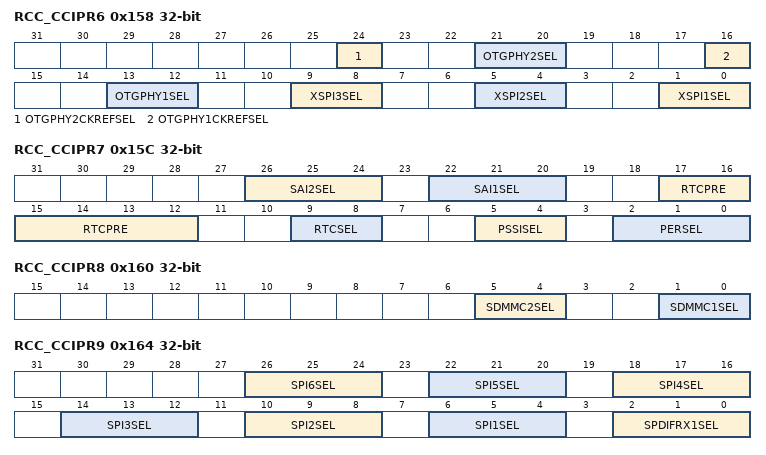
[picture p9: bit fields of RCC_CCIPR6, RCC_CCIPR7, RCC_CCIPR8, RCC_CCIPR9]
0x158 RCC_CCIPR6 — RCC clock configuration for independent peripheral register6
  [24] OTGPHY2CKREFSEL — Set and reset by software
  [21:20] OTGPHY2SEL — Source selection for the OTGPHY2 kernel clock
    0=hse_ck selected as reference clock; 1=per_ck selected as reference clock; 2=ic15_ck selected as reference clock; 3=hse_div2_osc_ck selected as reference clock
  [16] OTGPHY1CKREFSEL — Set and reset by software
  [13:12] OTGPHY1SEL — Source selection for the OTGPHY1 kernel clock
    values as OTGPHY2SEL
  [9:8] XSPI3SEL — Source selection for the XSPI3 kernel clock
    values as RCC_CCIPR3.FMCSEL
  [5:4] XSPI2SEL — Source selection for the XSPI2 kernel clock
    values as RCC_CCIPR3.FMCSEL
  [1:0] XSPI1SEL — Source selection for the XSPI1 kernel clock
    values as RCC_CCIPR3.FMCSEL
0x15C RCC_CCIPR7 — RCC clock configuration for independent peripheral register7
  [26:24] SAI2SEL — Source selection for the SAI2 kernel clock
    0=pclk2 selected as reference clock; 1=per_ck selected as reference clock; 2=ic7_ck selected as reference clock; 3=ic8_ck selected as reference clock; 4=msi_ck selected as reference clock; 5=hsi_div_ck selected as reference clock; 6=I2S_CKIN selected as reference clock; 7=spdif_symb_ck selected as reference clock
  [22:20] SAI1SEL — Source selection for the SAI1 kernel clock
    values as SAI2SEL
  [17:12] RTCPRE — RTC Prog clock divider selection (for clock ck_icn_p_risaf)
    {v}=ck_icn_p_risaf is divided by {v+1} (v=0..3); 63=ck_icn_p_risaf is divided by 64
  [9:8] RTCSEL — Source selection for the RTC kernel clock
    1=lse_ck selected as reference clock; 2=lsi_ck selected as reference clock; 3=hse_rtc_ck selected as reference clock
  [5:4] PSSISEL — Source selection for the PSSI kernel clock
    0=hclk5 selected as reference clock; 1=per_ck selected as reference clock; 2=ic20_ck selected as reference clock; 3=hsi_div_ck selected as reference clock
  [2:0] PERSEL — Source selection for the PER kernel clock
    0=hsi_ck selected as reference clock; 1=msi_ck selected as reference clock; 2=hse_ck selected as reference clock; 3=ic19_ck selected as reference clock; 4=ic5_ck selected as reference clock; 5=ic10_ck selected as reference clock; 6=ic15_ck selected as reference clock; 7=ic20_ck selected as reference clock
0x160 RCC_CCIPR8 — RCC clock configuration for independent peripheral register8
  [5:4] SDMMC2SEL — Source selection for the SDMMC2 kernel clock
    0=hclku selected as reference clock; 1=per_ck selected as reference clock; 2=ic4_ck selected as reference clock; 3=ic5_ck selected as reference clock
  [1:0] SDMMC1SEL — Source selection for the SDMMC1 kernel clock
    values as SDMMC2SEL
0x164 RCC_CCIPR9 — RCC clock configuration for independent peripheral register9
  [26:24] SPI6SEL — Source selection for the SPI6 kernel clock
    0=pclk4 selected as reference clock; 1=per_ck selected as reference clock; 2=ic8_ck selected as reference clock; 3=ic9_ck selected as reference clock; 4=msi_ck selected as reference clock; 5=hsi_div_ck selected as reference clock; 6=I2S_CKIN selected as reference clock
  [22:20] SPI5SEL — Source selection for the SPI5 kernel clock
    0=pclk2 selected as reference clock; 1=per_ck selected as reference clock; 2=ic9_ck selected as reference clock; 3=ic14_ck selected as reference clock; 4=msi_ck selected as reference clock; 5=hsi_div_ck selected as reference clock; 6=hse_ck selected as reference clock
  [18:16] SPI4SEL — Source selection for the SPI4 kernel clock
    values as SPI5SEL
  [14:12] SPI3SEL — Source selection for the SPI3 kernel clock
    0=pclk1 selected as reference clock; 1=per_ck selected as reference clock; 2=ic8_ck selected as reference clock; 3=ic9_ck selected as reference clock; 4=msi_ck selected as reference clock; 5=hsi_div_ck selected as reference clock; 6=I2S_CKIN selected as reference clock
  [10:8] SPI2SEL — Source selection for the SPI2 kernel clock
    values as SPI3SEL
  [6:4] SPI1SEL — Source selection for the SPI1 kernel clock
    0=pclk2 selected as reference clock; 1=per_ck selected as reference clock; 2=ic8_ck selected as reference clock; 3=ic9_ck selected as reference clock; 4=msi_ck selected as reference clock; 5=hsi_div_ck selected as reference clock; 6=I2S_CKIN selected as reference clock
  [2:0] SPDIFRX1SEL — Source selection for the SPDIFRX1 kernel clock
    0=pclk1 selected as reference clock; 1=per_ck selected as reference clock; 2=ic7_ck selected as reference clock; 3=ic8_ck selected as reference clock; 4=msi_ck selected as reference clock; 5=hsi_div_ck selected as reference clock; 6=I2S_CKIN selected as reference clock
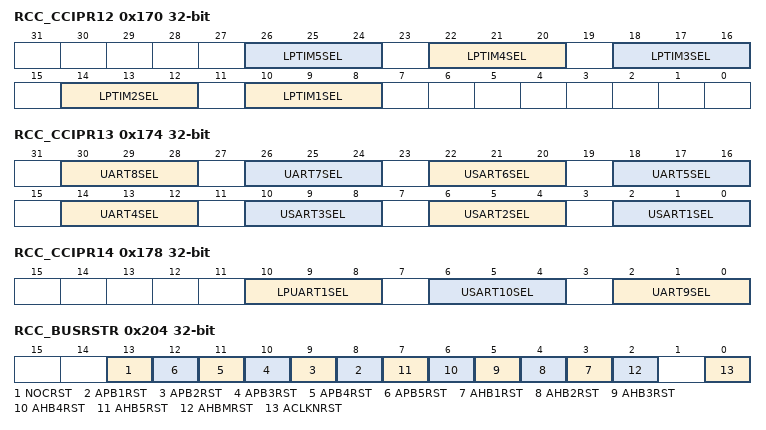
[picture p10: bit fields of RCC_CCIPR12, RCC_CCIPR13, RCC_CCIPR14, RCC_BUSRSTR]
0x170 RCC_CCIPR12 — RCC clock configuration for independent peripheral register12
  [4n+6:4n+4] LPTIM{n}SEL (n=2..5) — Source selection for the LPTIM{n} kernel clock
    0=pclk4 selected as reference clock; 1=per_ck selected as reference clock; 2=ic15_ck selected as reference clock; 3=lse_ck selected as reference clock; 4=lsi_ck selected as reference clock; 5=timg_ck selected as reference clock
  [10:8] LPTIM1SEL — Source selection for the LPTIM1 kernel clock
    0=pclk1 selected as reference clock; 1=per_ck selected as reference clock; 2=ic15_ck selected as reference clock; 3=lse_ck selected as reference clock; 4=lsi_ck selected as reference clock; 5=timg_ck selected as reference clock
0x174 RCC_CCIPR13 — RCC clock configuration for independent peripheral register13
  [30:28] UART8SEL — Source selection for the UART8 kernel clock
    0=pclk1 selected as reference clock; 1=per_ck selected as reference clock; 2=ic9_ck selected as reference clock; 3=ic14_ck selected as reference clock; 4=lse_ck selected as reference clock; 5=msi_ck selected as reference clock; 6=hsi_div_ck selected as reference clock
  [26:24] UART7SEL — Source selection for the UART7 kernel clock
    values as UART8SEL
  [22:20] USART6SEL — Source selection for the USART6 kernel clock
    0=pclk2 selected as reference clock; 1=per_ck selected as reference clock; 2=ic9_ck selected as reference clock; 3=ic14_ck selected as reference clock; 4=lse_ck selected as reference clock; 5=msi_ck selected as reference clock; 6=hsi_div_ck selected as reference clock
  [18:16] UART5SEL — Source selection for the UART5 kernel clock
    values as UART8SEL
  [14:12] UART4SEL — Source selection for the UART4 kernel clock
    values as UART8SEL
  [10:8] USART3SEL — Source selection for the USART3 kernel clock
    values as UART8SEL
  [6:4] USART2SEL — Source selection for the USART2 kernel clock
    values as UART8SEL
  [2:0] USART1SEL — Source selection for the USART1 kernel clock
    values as USART6SEL
0x178 RCC_CCIPR14 — RCC clock configuration for independent peripheral register14
  [10:8] LPUART1SEL — Source selection for the LPUART1 kernel clock
    0=pclk4 selected as reference clock; 1=per_ck selected as reference clock; 2=ic9_ck selected as reference clock; 3=ic14_ck selected as reference clock; 4=lse_ck selected as reference clock; 5=msi_ck selected as reference clock; 6=hsi_div_ck selected as reference clock
  [6:4] USART10SEL — Source selection for the USART10 kernel clock
    values as RCC_CCIPR13.USART6SEL
  [2:0] UART9SEL — Source selection for the UART9 kernel clock
    values as RCC_CCIPR13.USART6SEL
0x204 RCC_BUSRSTR — RCC SoC buses reset register
  [13] NOCRST — NOC reset
    0=NOC is not under reset (default after reset); 1=NOC is under reset
  [n+7] APB{n}RST (n=1..5) — APB{n} reset
    0=APB{n} is not under reset (default after reset); 1=APB{n} is under reset
  [n+2] AHB{n}RST (n=1..5) — AHB{n} reset
    0=AHB{n} is not under reset (default after reset); 1=AHB{n} is under reset
  [2] AHBMRST — AHBM reset
    0=AHBM is not under reset (default after reset); 1=AHBM is under reset
  [0] ACLKNRST — ACLKN reset
    0=ACLKN is not under reset (default after reset); 1=ACLKN is under reset
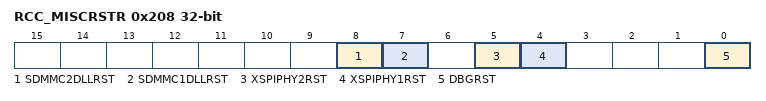
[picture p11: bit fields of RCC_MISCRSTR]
0x208 RCC_MISCRSTR — RCC miscellaneous configurations reset register
  [8] SDMMC2DLLRST — SDMMC2DLL reset
    0=SDMMC2DLL is not under reset (default after reset); 1=SDMMC2DLL is under reset
  [7] SDMMC1DLLRST — SDMMC1DLL reset
    0=SDMMC1DLL is not under reset (default after reset); 1=SDMMC1DLL is under reset
  [5] XSPIPHY2RST — XSPIPHY2 reset
    0=XSPIPHY2 is not under reset (default after reset); 1=XSPIPHY2 is under reset
  [4] XSPIPHY1RST — XSPIPHY1 reset
    0=XSPIPHY1 is not under reset (default after reset); 1=XSPIPHY1 is under reset
  [0] DBGRST — DBG reset
    0=DBG is not under reset (default after reset); 1=DBG is under reset
